# MIMXRT1021 register map
Vendor: nxp.com; File version: 1.0
CPU: CM7 r0p1, little endian, MPU, FPU, VTOR, 4 interrupt priority bits
Registers are 32-bit, read-write, reset 0x0 unless marked. A register's access mark holds for its fields unless they carry their own. Offsets are from the block's base; [hi:lo] are bit positions.

## DCDC
Base 0x40080000
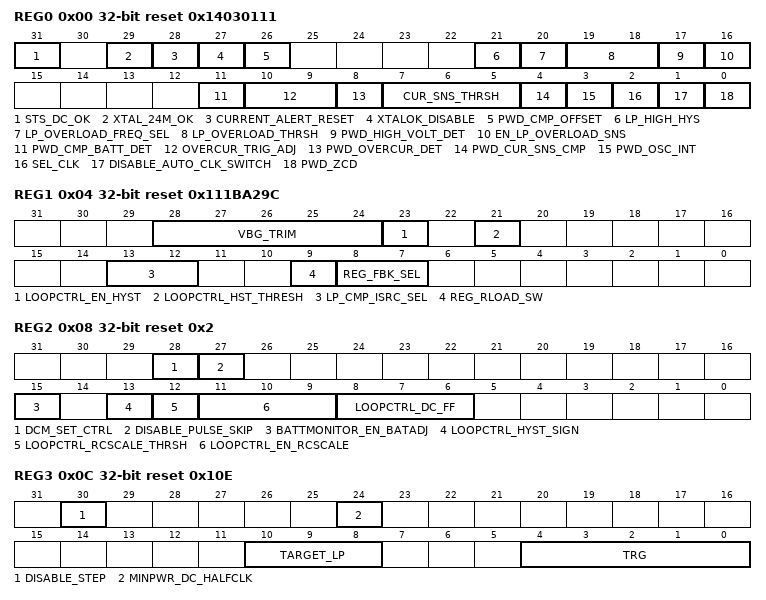
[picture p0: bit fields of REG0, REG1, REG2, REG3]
0x00 REG0 reset 0x14030111 — DCDC Register 0
  [31] STS_DC_OK ro — DCDC Output OK
    0=not_settled (DCDC is settling); 1=settled (DCDC already settled)
  [29] XTAL_24M_OK — 24M XTAL OK
    0=int_rng_osc (DCDC uses internal ring OSC); 1=xtal_24M (DCDC uses xtal 24M)
  [28] CURRENT_ALERT_RESET — Reset Current Alert Signal
    0=not_reset (Current Alert Signal not reset); 1=reset (Current Alert Signal reset)
  [27] XTALOK_DISABLE — Disable xtalok detection circuit
    0=enabled (Enable xtalok detection circuit); 1=disabled (Disable xtalok detection circuit and always outputs OK signal "1")
  [26] PWD_CMP_OFFSET — Power down output range comparator
    0=powered_up (Output range comparator powered up); 1=powered_down (Output range comparator powered down)
  [21] LP_HIGH_HYS — Low Power High Hysteric Value
    0=lp_12p5mV (Adjust hysteretic value in low power to 12.5mV); 1=lp_25mV (Adjust hysteretic value in low power to 25mV)
  [20] LP_OVERLOAD_FREQ_SEL — Low Power Overload Frequency Select
    0=eight_32k_cycle; 1=sixteen_32k_cycle
  [19:18] LP_OVERLOAD_THRSH — Low Power Overload Threshold
    0=thrsh_32 (32); 1=thrsh_64 (64); 2=thrsh_16 (16); 3=thrsh_8 (8)
  [17] PWD_HIGH_VOLT_DET — Power Down High Voltage Detection
    0=enabled (Overvoltage detection comparator is enabled); 1=disabled (Overvoltage detection comparator is disabled)
  [16] EN_LP_OVERLOAD_SNS — Low Power Overload Sense Enable
    0=disabled (Overload Detection in power save mode disabled); 1=enabled (Overload Detection in power save mode enabled)
  [11] PWD_CMP_BATT_DET — Power Down Battery Detection Comparator
    0=enabled (Low voltage detection comparator is enabled); 1=disabled (Low voltage detection comparator is disabled)
  [10:9] OVERCUR_TRIG_ADJ — Overcurrent Trigger Adjust
    0=select_zero (In Run Mode, 1 A. In Power Save Mode, 0.25 A); 1=select_one (In Run Mode, 2 A. In Power Save Mode, 0.25 A); 2=select_two (In Run Mode, 1 A. In Power Save Mode, 0.2 A); 3=select_three (In Run Mode, 2 A. In Power Save Mode, 0.2 A)
  [8] PWD_OVERCUR_DET — Power down overcurrent detection comparator
    0=enabled (Overcurrent detection comparator is enabled); 1=disabled (Overcurrent detection comparator is disabled)
  [7:5] CUR_SNS_THRSH — Current Sense (detector) Threshold
    0=select_zero (150 mA); 1=select_one (250 mA); 2=select_two (350 mA); 3=select_three (450 mA); 4=select_four (550 mA); 5=select_five (650 mA)
  [4] PWD_CUR_SNS_CMP — Power down signal of the current detector.
    0=powered_up (Current Detector powered up); 1=powered_down (Current Detector powered down)
  [3] PWD_OSC_INT — Power down internal osc
    0=powered_up (Internal oscillator powered up); 1=powered_down (Internal oscillator powered down)
  [2] SEL_CLK — Select Clock
    0=int_rng_osc (DCDC uses internal ring oscillator); 1=xtal_24M (DCDC uses 24M xtal)
  [1] DISABLE_AUTO_CLK_SWITCH — Disable Auto Clock Switch
    0=xtal_clk (If DISABLE_AUTO_CLK_SWITCH is set to 0 and 24M xtal is OK, the clock source will switch from internal ring OSC to 24M xtal automatically); 1=sel_clk (If DISABLE_AUTO_CLK_SWITCH is set to 1, SEL_CLK will determine which clock source the DCDC uses)
  [0] PWD_ZCD — Power Down Zero Cross Detection
    0=powered_up (Zero cross detetion function powered up); 1=powered_down (Zero cross detetion function powered down)
0x04 REG1 reset 0x111BA29C — DCDC Register 1
  [28:24] VBG_TRIM — Trim Bandgap Voltage
  [23] LOOPCTRL_EN_HYST — Enable Hysteresis
    0=Disable hysteresis in switching converter common mode analog comparators; 1=Enable hysteresis in switching converter common mode analog comparators
  [21] LOOPCTRL_HST_THRESH — Increase Threshold Detection
    0=low_hyst_thresh (Lower hysteresis threshold (about 2.5mV in typical, but this value can vary with PVT corners); 1=high_hyst_thresh (Higher hysteresis threshold (about 5mV in typical))
  [13:12] LP_CMP_ISRC_SEL — Low Power Comparator Current Bias
    0=sel0 (50 nA); 1=sel1 (100 nA); 2=sel2 (200 nA); 3=sel3 (400 nA)
  [9] REG_RLOAD_SW — This controls the load resistor of the internal regulator of DCDC
    0=loadR_disconnect (Load resistor disconnected); 1=loadR_connect (Load resistor connected)
  [8:7] REG_FBK_SEL — Select the feedback point of the internal regulator
    0=The regulator outputs 1.0V with 1.2V reference voltage; 1=The regulator outputs 1.1V with 1.2V reference voltage; 2=The regulator outputs 1.0V with 1.3V reference voltage; 3=The regulator outputs 1.1V with 1.3V reference voltage
0x08 REG2 reset 0x2 — DCDC Register 2
  [28] DCM_SET_CTRL — DCM Set Control
  [27] DISABLE_PULSE_SKIP
    0=idle (DCDC will be idle to save current dissipation when the duty cycle get to the low limit which is set by NEGLIMIT_IN.); 1=not_idle (DCDC will keep working with the low limited duty cycle NEGLIMIT_IN.)
  [15] BATTMONITOR_EN_BATADJ — This bit enables the DC-DC to improve efficiency and minimize ripple using the information from the BATT_VAL field
  [13] LOOPCTRL_HYST_SIGN — Invert the sign of the hysteresis in DC-DC analog comparators.
    0=noinvert (Do not invert sign of the hysteresis); 1=Invert sign of the hysteresis
  [12] LOOPCTRL_RCSCALE_THRSH — Increase the threshold detection for RC scale circuit.
    0=no_increase_thrsh (Do not increase the threshold detection for RC scale circuit.); 1=increase_thrsh (Increase the threshold detection for RC scale circuit.)
  [11:9] LOOPCTRL_EN_RCSCALE — Enable RC Scale
  [8:6] LOOPCTRL_DC_FF — Two's complement feed forward step in duty cycle in the switching DC-DC converter
0x0C REG3 reset 0x10E — DCDC Register 3
  [30] DISABLE_STEP
    0=Enable stepping for the output of VDD_SOC of DCDC; 1=Disable stepping for the output of VDD_SOC of DCDC
  [24] MINPWR_DC_HALFCLK — Set DCDC clock to half frequency for continuous mode
    0=fullfreq (DCDC clock remains at full frequency for continuous mode); 1=halffreq (DCDC clock set to half frequency for continuous mode)
  [10:8] TARGET_LP — Low Power Target Value
    0=sel0 (0.9 V); 1=sel1 (0.925 V); 2=sel2 (0.95 V); 3=sel3 (0.975 V); 4=sel4 (1.0 V)
  [4:0] TRG — Target value of VDD_SOC

## Notices in the file
Copyright 2016-2020 NXP
All rights reserved.
SPDX-License-Identifier: BSD-3-Clause
